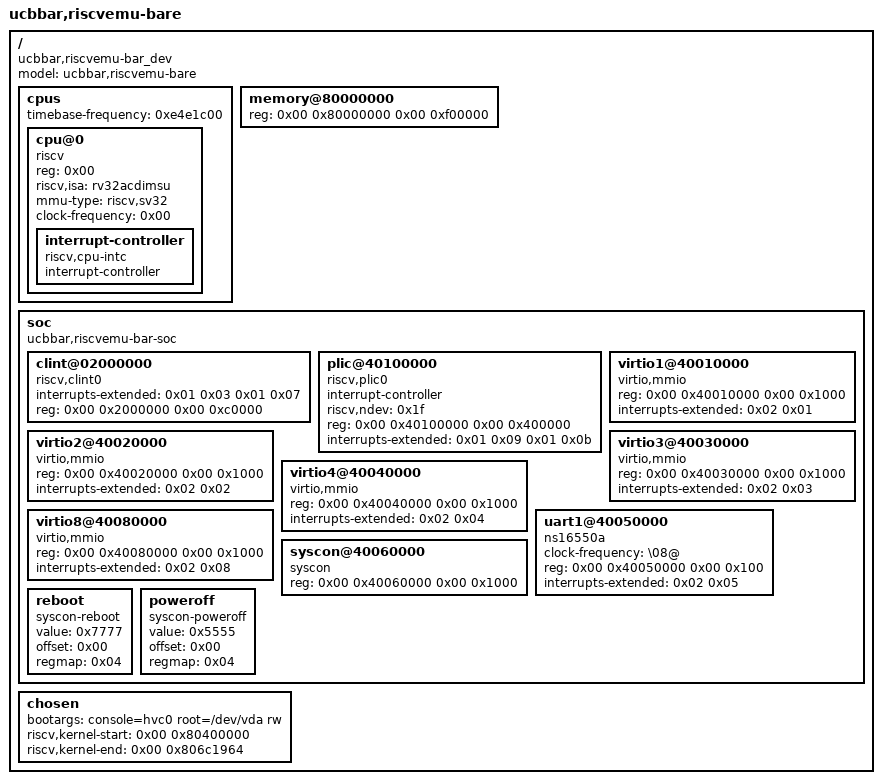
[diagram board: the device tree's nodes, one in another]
/dts-v1/;

/ {
	#address-cells = <0x02>;
	#size-cells = <0x02>;
	compatible = "ucbbar,riscvemu-bar_dev";
	model = "ucbbar,riscvemu-bare";

	cpus {
		#address-cells = <0x01>;
		#size-cells = <0x00>;
		timebase-frequency = <0xe4e1c00>;

		cpu@0 {
			device_type = "cpu";
			reg = <0x00>;
			status = "okay";
			compatible = "riscv";
			riscv,isa = "rv32acdimsu";
			mmu-type = "riscv,sv32";
			clock-frequency = <0x00>;

			interrupt-controller {
				#interrupt-cells = <0x01>;
				interrupt-controller;
				compatible = "riscv,cpu-intc";
				phandle = <0x01>;
			};
		};
	};

	memory@80000000 {
		device_type = "memory";
		reg = <0x00 0x80000000 0x00 0xf00000>;
	};

	soc {
		#address-cells = <0x02>;
		#size-cells = <0x02>;
		compatible = "ucbbar,riscvemu-bar-soc\0simple-bus";
		ranges;

		clint@02000000 {
			compatible = "riscv,clint0";
			interrupts-extended = <0x01 0x03 0x01 0x07>;
			reg = <0x00 0x2000000 0x00 0xc0000>;
		};

		plic@40100000 {
			#interrupt-cells = <0x01>;
			interrupt-controller;
			compatible = "riscv,plic0";
			riscv,ndev = <0x1f>;
			reg = <0x00 0x40100000 0x00 0x400000>;
			interrupts-extended = <0x01 0x09 0x01 0x0b>;
			phandle = <0x02>;
		};

		virtio1@40010000 {
			compatible = "virtio,mmio";
			reg = <0x00 0x40010000 0x00 0x1000>;
			interrupts-extended = <0x02 0x01>;
		};

		virtio2@40020000 {
			compatible = "virtio,mmio";
			reg = <0x00 0x40020000 0x00 0x1000>;
			interrupts-extended = <0x02 0x02>;
		};

		virtio3@40030000 {
			compatible = "virtio,mmio";
			reg = <0x00 0x40030000 0x00 0x1000>;
			interrupts-extended = <0x02 0x03>;
		};

		virtio4@40040000 {
			compatible = "virtio,mmio";
			reg = <0x00 0x40040000 0x00 0x1000>;
			interrupts-extended = <0x02 0x04>;
		};

		virtio8@40080000 {
			compatible = "virtio,mmio";
			reg = <0x00 0x40080000 0x00 0x1000>;
			interrupts-extended = <0x02 0x08>;
		};

		uart1@40050000 {
			compatible = "ns16550a";
			clock-frequency = "\08@";
			reg = <0x00 0x40050000 0x00 0x100>;
			interrupts-extended = <0x02 0x05>;
		};

		syscon@40060000 {
			phandle = <0x04>;
			reg = <0x00 0x40060000 0x00 0x1000>;
			compatible = "syscon";
		};

		reboot {
			value = <0x7777>;
			offset = <0x00>;
			regmap = <0x04>;
			compatible = "syscon-reboot";
		};

		poweroff {
			value = <0x5555>;
			offset = <0x00>;
			regmap = <0x04>;
			compatible = "syscon-poweroff";
		};
	};

	chosen {
		bootargs = "console=hvc0 root=/dev/vda rw";
		riscv,kernel-start = <0x00 0x80400000>;
		riscv,kernel-end = <0x00 0x806c1964>;
	};
};
